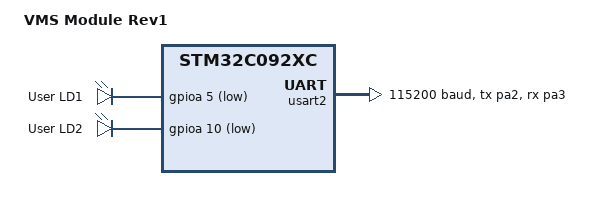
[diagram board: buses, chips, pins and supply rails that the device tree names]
/*
 * VMS Module Rev1, based on STM32C092RCT6 (LQFP64)
 * Derived loosely from NUCLEO-C092RC, no HSE/LSE crystals.
 */
/dts-v1/;
#include <st/c0/stm32c092Xc.dtsi>
#include <st/c0/stm32c092r(b-c)tx-pinctrl.dtsi>

/ {
	model = "VMS Module Rev1";
	compatible = "vmsboards,vms-module-rev1";

	chosen {
		zephyr,console = &usart2;
		zephyr,shell-uart = &usart2;
		zephyr,sram = &sram0;
		zephyr,flash = &flash0;
	};

	leds {
		compatible = "gpio-leds";

		/* TODO: verify pins against YOUR schematic (taken from Nucleo layout) */
		led1: led_1 {
			gpios = <&gpioa 5 GPIO_ACTIVE_LOW>;
			label = "User LD1";
		};
		led2: led_2 {
			gpios = <&gpioa 10 GPIO_ACTIVE_LOW>;
			label = "User LD2";
		};
	};

	aliases {
		led0 = &led1;
		led1 = &led2;
	};
};

/* No external oscillators: run SYSCLK straight from the internal HSI (48 MHz) */
&clk_hsi {
	status = "okay";
	hsi-div = <1>;
};

&rcc {
	clocks = <&clk_hsi>;
	clock-frequency = <DT_FREQ_M(48)>;
	ahb-prescaler = <1>;
	apb1-prescaler = <1>;
};

/* No LSE fitted: use the LSI for RTC/IWDG */
&clk_lsi {
	status = "okay";
};

/* ST-LINK virtual COM port via STDC14 (verify USART + pins on your board) */
&usart2 {
	pinctrl-0 = <&usart2_tx_pa2 &usart2_rx_pa3>;
	pinctrl-names = "default";
	current-speed = <115200>;
	status = "okay";
};
